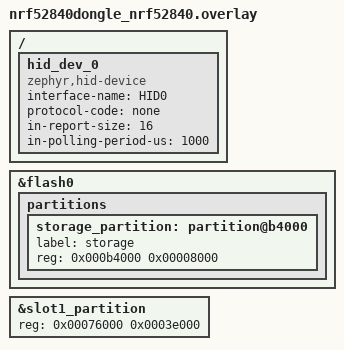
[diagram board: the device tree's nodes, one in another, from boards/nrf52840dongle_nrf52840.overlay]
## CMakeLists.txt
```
# SPDX-License-Identifier: Apache-2.0
cmake_minimum_required(VERSION 3.20.0)

find_package(Zephyr REQUIRED HINTS $ENV{ZEPHYR_BASE})
project(voice_keyboard)

target_include_directories(app PRIVATE src)
target_sources(app PRIVATE
  src/main.c
  src/usb_kbd.c
  src/ble.c
  src/inputstick.c
  # v6.0: src/typing.c (v2..v5 legacy raw ASCII/escape stream) superseded by
  # the InputStick packet protocol — removed from the build; the file stays
  # in the tree as a reference (see DEBUG_NOTES.md v6.0).
  # v5.14: src/macro.c (dongle-stored macro store) excluded — the macro
  # GATT surface hung every v5.x/v5.12/v5.13 build on hardware and is
  # removed for good; the file stays in the tree as a reference
  # (see DEBUG_NOTES.md v5.14).
)
```

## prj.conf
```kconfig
# Voice Keyboard — nRF52840 dongle (PCA10059), Adafruit UF2 bootloader

# --- UF2 drag-and-drop output; Adafruit bootloader layout (app @ 0x26000) ---
# App must stay below the storage partition (0xB4000, see boards overlay).
CONFIG_BUILD_OUTPUT_UF2=y
CONFIG_FLASH_LOAD_OFFSET=0x26000
CONFIG_FLASH_LOAD_SIZE=0x8E000

# --- USB HID keyboard (next USB device stack) ---
# The board defconfig force-enables the legacy stack + CDC ACM console;
# turn it off so only the next stack owns the USBD peripheral.
CONFIG_USB_DEVICE_STACK=n
CONFIG_USB_CDC_ACM=n
CONFIG_USB_DEVICE_STACK_NEXT=y
CONFIG_USBD_HID_SUPPORT=y

# --- BLE peripheral: NUS (defined in-app) + DIS ---
# v6.0: no pairing/bonding/encryption — SMP is removed, RX is plain write,
# and the device advertises as "InputStick" (see INPUTSTICK_EMULATION_SPEC.md).
CONFIG_BT=y
CONFIG_BT_PERIPHERAL=y
CONFIG_BT_DEVICE_NAME="InputStick"
CONFIG_BT_DIS=y
CONFIG_BT_DIS_FW_REV=y
CONFIG_BT_DIS_FW_REV_STR="vk-6.7-fix"

# --- ATT MTU headroom (added in v5 for 180-byte macro chunks; kept since
# v5.6/v5.14 after the macro store was stripped so the on-air link stays
# unchanged) ---
# Negotiated ATT MTU = min(L2CAP RX/TX MTU); defaults (65) are too small.
CONFIG_BT_BUF_ACL_RX_SIZE=200
CONFIG_BT_L2CAP_TX_MTU=200
# Keep the controller PDU length at the v4 default: BT_CTLR_DATA_LENGTH_MAX
# would otherwise follow BT_BUF_ACL_RX_SIZE to 200. The host-side MTU only
# needs L2CAP (re)assembly, so pinning this keeps the on-air link layer
# byte-identical to the hardware-verified v4 build.
CONFIG_BT_CTLR_DATA_LENGTH_MAX=27

# --- Settings/NVS (storage partition) ---
# v6.0: no bonds to persist, but the settings subsystem + storage partition
# stay so the v5.2 NVS mount/repair path in ble_init() keeps guarding
# bt_enable() against garbage flash at 0xB4000.
CONFIG_BT_SETTINGS=y
CONFIG_FLASH=y
CONFIG_FLASH_MAP=y
CONFIG_NVS=y
CONFIG_SETTINGS=y
CONFIG_SETTINGS_NVS=y

# --- Button + LED ---
CONFIG_GPIO=y

# --- Headless build: no UART console, log to SEGGER RTT ---
CONFIG_CONSOLE=n
CONFIG_SERIAL=n
CONFIG_UART_CONSOLE=n
CONFIG_LOG=y
CONFIG_LOG_DEFAULT_LEVEL=3
CONFIG_USE_SEGGER_RTT=y
CONFIG_LOG_BACKEND_RTT=y

CONFIG_MAIN_STACK_SIZE=2048
CONFIG_SYSTEM_WORKQUEUE_STACK_SIZE=2048
```

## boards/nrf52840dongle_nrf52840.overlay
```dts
/*
 * Voice Keyboard — nRF52840 dongle additions.
 * The board DTS already enables zephyr_udc0; we only need the HID device node.
 */

/ {
	hid_dev_0: hid_dev_0 {
		compatible = "zephyr,hid-device";
		interface-name = "HID0";
		/* Composite keyboard (report ID 1) + mouse (report ID 2): the
		 * report descriptor uses report IDs, which is incompatible
		 * with the HID boot protocol, so no boot protocol is claimed.
		 */
		protocol-code = "none";
		/* Longest input report: keyboard = 1 ID byte + 8 report bytes.
		 * MPS must be a power of two (16) — 9-byte keyboard reports ride
		 * as short packets on the 16-byte endpoint, normal for
		 * interrupt IN. A non-power-of-2 MPS (9) is a suspected
		 * host-side drop trigger.
		 */
		in-report-size = <16>;
		in-polling-period-us = <1000>;
	};
};

/* v5: the stock 16 KB storage partition (4 NVS sectors) cannot hold the
 * 16 KB macro store alongside the bonds (NVS needs a free
 * sector for GC). Move storage into the tail of the unused slot1 (image-1)
 * partition and enlarge it to 32 KB (8 sectors). The app is capped below
 * 0xB4000 via CONFIG_FLASH_LOAD_SIZE. Side effect: bonds stored by
 * firmware <= v4 live in the old partition and are not migrated — re-pair
 * once after flashing v5.
 */
&flash0 {
	partitions {
		/delete-node/ partition@dc000;
		storage_partition: partition@b4000 {
			label = "storage";
			reg = <0x000b4000 0x00008000>;
		};
	};
};

&slot1_partition {
	reg = <0x00076000 0x0003e000>;
};
```

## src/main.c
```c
/* Voice Keyboard — application glue: LED feedback, button, init. */

#include <zephyr/kernel.h>
#include <zephyr/drivers/gpio.h>
#include <zephyr/fatal.h>

#include <zephyr/logging/log.h>
LOG_MODULE_REGISTER(main, LOG_LEVEL_INF);

#include "vkb.h"

/* Green LED (led0): slow blink = advertising, solid = connected. */
static const struct gpio_dt_spec led = GPIO_DT_SPEC_GET(DT_ALIAS(led0), gpios);

/* Red debug LED (led1): temporary bring-up aid, see DEBUG_NOTES.md. */
static const struct gpio_dt_spec dbg_led =
	GPIO_DT_SPEC_GET_OR(DT_ALIAS(led1), gpios, {0});

/* v6.6-diagnostic: latched drain indicator (0 = never nonzero, 1 = nonzero
 * seen at least once). Set by app_drain_latch_set() from inputstick.c's
 * send_hid_status(); see DEBUG_NOTES.md v6.6-diagnostic.
 */
static atomic_t drain_latch;

static uint8_t dbg_pulses;
static uint16_t dbg_on_ms;
static uint16_t dbg_off_ms;
static bool dbg_led_on;

static void dbg_led_work_handler(struct k_work *work);

static K_WORK_DELAYABLE_DEFINE(dbg_led_work, dbg_led_work_handler);

static void dbg_led_work_handler(struct k_work *work)
{
	ARG_UNUSED(work);

	if (dbg_led_on) {
		gpio_pin_set_dt(&dbg_led, 0);
		dbg_led_on = false;
		if (dbg_pulses > 0) {
			k_work_reschedule(&dbg_led_work, K_MSEC(dbg_off_ms));
		}
		return;
	}

	if (dbg_pulses > 0) {
		dbg_pulses--;
		gpio_pin_set_dt(&dbg_led, 1);
		dbg_led_on = true;
		k_work_reschedule(&dbg_led_work, K_MSEC(dbg_on_ms));
	}
}

/* Boot-stage trace (v5.1): N slow red blinks = stage N completed, so a
 * boot hang on the headless dongle is pinpointed by the last code seen.
 * Codes (execution order, documented in DEBUG_NOTES.md):
 *   1 = main() entered, 2 = USB HID up, 3 = BLE stack up (bt_enable),
 *   4 = settings loaded, 5 = advertising up.
 * No blinks at all = death before main() (kernel/driver init).
 */
void app_boot_stage(uint8_t stage)
{
	if (dbg_led.port == NULL) {
		return;
	}

	for (uint8_t i = 0; i < stage; i++) {
		gpio_pin_set_dt(&dbg_led, 1);
		k_msleep(80);
		gpio_pin_set_dt(&dbg_led, 0);
		k_msleep(80);
	}
	k_msleep(300); /* gap between stage codes */
}

/* Boot sub-stage markers (v5.2): long (400 ms) red blinks, used for the
 * sub-steps inside ble_init()'s bt_enable() path that the short stage
 * codes can't distinguish. See DEBUG_NOTES.md.
 */
void app_boot_mark(uint8_t count)
{
	if (dbg_led.port == NULL) {
		return;
	}

	for (uint8_t i = 0; i < count; i++) {
		gpio_pin_set_dt(&dbg_led, 1);
		k_msleep(400);
		gpio_pin_set_dt(&dbg_led, 0);
		k_msleep(400);
	}
	k_msleep(300);
}

/* Repeating fast blink: bt_enable() returned an error. Never returns. */
void app_boot_error_bt(void)
{
	for (;;) {
		if (dbg_led.port != NULL) {
			gpio_pin_set_dt(&dbg_led, 1);
			k_msleep(100);
			gpio_pin_set_dt(&dbg_led, 0);
		}
		k_msleep(100);
	}
}

/* Repeating 3-long-blink group: settings storage unrecoverable even
 * after erasing the partition. Never returns.
 */
void app_boot_error_settings(void)
{
	for (;;) {
		if (dbg_led.port != NULL) {
			for (uint8_t i = 0; i < 3; i++) {
				gpio_pin_set_dt(&dbg_led, 1);
				k_msleep(400);
				gpio_pin_set_dt(&dbg_led, 0);
				k_msleep(400);
			}
		}
		k_msleep(1200);
	}
}

/* Fatal-error handler (v5.2): a fault anywhere — including inside
 * bt_enable(), where the boot-stage trace can't see it — used to die
 * silently with the red LED frozen at the last stage code (no reset:
 * CONFIG_RESET_ON_FAULT=n). Signal it with a continuous slow (1 s) red
 * blink instead. Interrupts may be disabled here, so busy-wait, never
 * k_msleep().
 */
void k_sys_fatal_error_handler(unsigned int reason, const struct arch_esf *esf)
{
	ARG_UNUSED(esf);

	LOG_ERR("Fatal error %u", reason);

	if (dbg_led.port != NULL) {
		gpio_pin_configure_dt(&dbg_led, GPIO_OUTPUT_INACTIVE);
		for (;;) {
			gpio_pin_set_dt(&dbg_led, 1);
			k_busy_wait(1000000);
			gpio_pin_set_dt(&dbg_led, 0);
			k_busy_wait(1000000);
		}
	}

	for (;;) {
		/* halt */
	}
}

void app_led_debug(enum app_led_code code)
{
	/* v6.6-diagnostic: DISABLED (no-op). The single red LED carried too
	 * many overlapping pulse codes to read on hardware (RX-write 1-blink,
	 * callback heartbeat, handshake/connect codes 9/12/13, HID fail,
	 * mouse/abs RX, and the v6.5 drain pulses). This early return silences
	 * them all; app_drain_latch_set() now drives the LED directly. The
	 * switch below is retained (not deleted) so re-enabling is a one-line
	 * revert.
	 */
	ARG_UNUSED(code);
	return;

	if (dbg_led.port == NULL) {
		return;
	}

	switch (code) {
	case APP_LED_RX_WRITE:
		dbg_on_ms = 80; dbg_off_ms = 80; dbg_pulses = 1;
		break;
	case APP_LED_HID_SENT:
		dbg_on_ms = 80; dbg_off_ms = 80; dbg_pulses = 2;
		break;
	case APP_LED_HID_FAIL:
		dbg_on_ms = 120; dbg_off_ms = 120; dbg_pulses = 3;
		break;
	case APP_LED_HID_READY:
		dbg_on_ms = 1000; dbg_off_ms = 0; dbg_pulses = 1;
		break;
	case APP_LED_MOUSE_RX:
		dbg_on_ms = 60; dbg_off_ms = 60; dbg_pulses = 4;
		break;
	case APP_LED_ABS_RX:
		dbg_on_ms = 60; dbg_off_ms = 60; dbg_pulses = 5;
		break;
	case APP_LED_MACRO_PLAY:
		dbg_on_ms = 60; dbg_off_ms = 60; dbg_pulses = 6;
		break;
	/* Connect-stage trace (v5.3): longer pulses so the counts stay
	 * distinguishable from the RX/HID codes above.
	 */
	case APP_LED_CONN_REJECT:
		dbg_on_ms = 200; dbg_off_ms = 200; dbg_pulses = 7;
		break;
	case APP_LED_SEC_FAIL:
		dbg_on_ms = 200; dbg_off_ms = 200; dbg_pulses = 8;
		break;
	case APP_LED_TX_SUB:
		dbg_on_ms = 200; dbg_off_ms = 200; dbg_pulses = 9;
		break;
	case APP_LED_NAME_READ:
		dbg_on_ms = 200; dbg_off_ms = 200; dbg_pulses = 10;
		break;
	case APP_LED_IS_CRC_FAIL:
		dbg_on_ms = 200; dbg_off_ms = 200; dbg_pulses = 2;
		break;
	case APP_LED_IS_PKT:
		dbg_on_ms = 200; dbg_off_ms = 200; dbg_pulses = 3;
		break;
	case APP_LED_IS_READY:
		dbg_on_ms = 200; dbg_off_ms = 200; dbg_pulses = 4;
		break;
	/* v6.5-diagnostic: drain-count ground truth (see DEBUG_NOTES.md
	 * v6.5-diagnostic). 3 fast blinks = a nonzero drain was computed this
	 * status interval; 1 long blink = all three drains are 0.
	 */
	case APP_LED_DRAIN_NONZERO:
		dbg_on_ms = 50; dbg_off_ms = 50; dbg_pulses = 3;
		break;
	case APP_LED_DRAIN_ZERO:
		dbg_on_ms = 200; dbg_off_ms = 0; dbg_pulses = 1;
		break;
	default:
		return;
	}

	if (!dbg_led_on) {
		k_work_reschedule(&dbg_led_work, K_NO_WAIT);
	}
}

/* v6.6-diagnostic: one-way drain latch. inputstick.c send_hid_status() calls
 * this the first time it sees any nonzero drain count; it sets the flag and
 * turns the red LED SOLID directly (no pulse work item), guarded on the LED
 * existing. Solid red = "drain went nonzero at least once"; dark red =
 * "drain always zero". The latch never clears, so solid stays solid.
 */
void app_drain_latch_set(void)
{
	atomic_set(&drain_latch, 1);
	if (dbg_led.port != NULL) {
		gpio_pin_set_dt(&dbg_led, 1);
	}
}

/* Onboard button (sw0). v5.3-v5.8: a short press opened the 60 s pairing
 * window; v5-v5.13: a long press (>1.5 s) played macro slot 0. Both are
 * gone in v6.0 (pairing removed; macro store removed in v5.14) — the button
 * is kept wired (debounced) but does nothing.
 */
static const struct gpio_dt_spec button = GPIO_DT_SPEC_GET(DT_ALIAS(sw0), gpios);

#define LONG_PRESS_MS	1500

static int64_t press_start;
static bool press_valid;

enum led_state {
	LED_OFF,
	LED_BLINK,
	LED_ON,
};

static volatile enum led_state led_state = LED_OFF;
static bool led_level;

void app_led_advertising(void)
{
	led_state = LED_BLINK;
}

void app_led_connected(void)
{
	led_state = LED_ON;
	gpio_pin_set_dt(&led, 1);
	led_level = true;
}

void app_led_off(void)
{
	led_state = LED_OFF;
	gpio_pin_set_dt(&led, 0);
	led_level = false;
}

static void led_timer_handler(struct k_timer *timer)
{
	ARG_UNUSED(timer);

	if (led_state == LED_BLINK) {
		led_level = !led_level;
		gpio_pin_set_dt(&led, led_level);
	}
}

/* 500 ms toggle -> 1 Hz blink. */
static K_TIMER_DEFINE(led_timer, led_timer_handler, NULL);

static void button_work_handler(struct k_work *work)
{
	ARG_UNUSED(work);

	/* Debounced: sample the pin after the delay. Interrupts fire on both
	 * edges, so this runs once per settled press and once per release.
	 */
	if (gpio_pin_get_dt(&button) == 1) {
		press_start = k_uptime_get();
		press_valid = true;
		return;
	}

	if (!press_valid) {
		return;
	}
	press_valid = false;

	if (k_uptime_get() - press_start >= LONG_PRESS_MS) {
		LOG_INF("Long press ignored (no macro store, no pairing)");
		return;
	}

	LOG_INF("Button pressed (no action in v6.0)");
}

static K_WORK_DELAYABLE_DEFINE(button_work, button_work_handler);

static void button_isr(const struct device *dev,
		       struct gpio_callback *cb, uint32_t pins)
{
	ARG_UNUSED(dev); ARG_UNUSED(cb); ARG_UNUSED(pins);

	k_work_reschedule(&button_work, K_MSEC(30));
}

static struct gpio_callback button_cb_data;

static int button_init(void)
{
	int ret;

	if (!gpio_is_ready_dt(&button)) {
		LOG_ERR("Button device not ready");
		return -ENODEV;
	}

	ret = gpio_pin_configure_dt(&button, GPIO_INPUT);
	if (ret) {
		return ret;
	}

	ret = gpio_pin_interrupt_configure_dt(&button, GPIO_INT_EDGE_BOTH);
	if (ret) {
		return ret;
	}

	gpio_init_callback(&button_cb_data, button_isr, BIT(button.pin));
	gpio_add_callback(button.port, &button_cb_data);

	return 0;
}

int main(void)
{
	int ret;

	if (gpio_is_ready_dt(&led)) {
		gpio_pin_configure_dt(&led, GPIO_OUTPUT_INACTIVE);
	} else {
		LOG_WRN("LED not available, continuing without it");
	}

	if (dbg_led.port != NULL && gpio_is_ready_dt(&dbg_led)) {
		gpio_pin_configure_dt(&dbg_led, GPIO_OUTPUT_INACTIVE);
	}

	k_timer_start(&led_timer, K_MSEC(500), K_MSEC(500));

	app_boot_stage(1);

	ret = button_init();
	if (ret) {
		LOG_ERR("Button init failed (%d), continuing without it", ret);
	}

	ret = usb_kbd_init();
	if (ret) {
		LOG_ERR("USB init failed (%d)", ret);
		return ret;
	}

	app_boot_stage(2);

	ret = ble_init();
	if (ret) {
		LOG_ERR("BLE init failed (%d)", ret);
		return ret;
	}

	LOG_INF("Voice Keyboard ready");
	return 0;
}
```

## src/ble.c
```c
/* Voice Keyboard — BLE peripheral (v6.0).
 *
 * Plain NUS peripheral: the standard Nordic UART service UUIDs with
 * unencrypted RX writes and no pairing/bonding — the InputStick iOS/Android
 * apps connect and write plaintext (see INPUTSTICK_EMULATION_SPEC.md §2).
 * The v5.3–v5.8 encryption/bonding machinery (bonded-peer gate, 60 s pairing
 * window, forced bt_conn_set_security, DisplayYesNo numeric-comparison
 * pairing, BT_GATT_PERM_WRITE_ENCRYPT) is stripped. The device advertises as
 * "InputStick".
 *
 * v5.14 removed the v5 MACRO_LIST/MACRO_RW macro-store characteristics for
 * good; macro.c stays in the tree as a reference but is excluded from the
 * build (see DEBUG_NOTES.md v5.14).
 */

#include <zephyr/kernel.h>
#include <zephyr/bluetooth/bluetooth.h>
#include <zephyr/bluetooth/conn.h>
#include <zephyr/bluetooth/gatt.h>
#include <zephyr/bluetooth/uuid.h>
#include <zephyr/settings/settings.h>
#include <zephyr/storage/flash_map.h>
#include <zephyr/sys/util.h>

#include <string.h>

#include <zephyr/logging/log.h>
LOG_MODULE_REGISTER(ble, LOG_LEVEL_INF);

#include "vkb.h"

/* Zephyr keeps settings_subsys_init() out of the public headers
 * (subsys/settings/src/settings_init.c). bt_enable() calls it internally
 * via bt_settings_init(); declared here so ble_init() can mount the
 * settings backend first — see ble_init().
 */
extern int settings_subsys_init(void);

/* Standard NUS UUIDs (we define the service in-app so the RX
 * characteristic uses plain BT_GATT_PERM_WRITE — Zephyr's built-in NUS
 * is equivalent, but defining it keeps the attribute layout explicit).
 */
#define VKB_UUID_NUS_SERVICE \
	BT_UUID_DECLARE_128(BT_UUID_128_ENCODE(0x6e400001, 0xb5a3, 0xf393, 0xe0a9, 0xe50e24dcca9e))
#define VKB_UUID_NUS_RX \
	BT_UUID_DECLARE_128(BT_UUID_128_ENCODE(0x6e400002, 0xb5a3, 0xf393, 0xe0a9, 0xe50e24dcca9e))
#define VKB_UUID_NUS_TX \
	BT_UUID_DECLARE_128(BT_UUID_128_ENCODE(0x6e400003, 0xb5a3, 0xf393, 0xe0a9, 0xe50e24dcca9e))

/* Fixed advertising/GAP name. */
#define DEVICE_NAME_DEFAULT	"InputStick"

static struct bt_conn *current_conn;
static bool tx_notif_enabled;

static ssize_t nus_rx_write(struct bt_conn *conn,
			    const struct bt_gatt_attr *attr,
			    const void *buf, uint16_t len,
			    uint16_t offset, uint8_t flags)
{
	ARG_UNUSED(conn); ARG_UNUSED(attr); ARG_UNUSED(offset); ARG_UNUSED(flags);

	app_led_debug(APP_LED_RX_WRITE);
	inputstick_feed(buf, len);
	return len;
}

static void nus_tx_ccc_changed(const struct bt_gatt_attr *attr, uint16_t value)
{
	ARG_UNUSED(attr);

	tx_notif_enabled = (value == BT_GATT_CCC_NOTIFY);
	if (tx_notif_enabled) {
		app_led_debug(APP_LED_TX_SUB);
	}
}

BT_GATT_SERVICE_DEFINE(nus_svc,
	BT_GATT_PRIMARY_SERVICE(VKB_UUID_NUS_SERVICE),
	BT_GATT_CHARACTERISTIC(VKB_UUID_NUS_TX,
		BT_GATT_CHRC_NOTIFY,
		BT_GATT_PERM_NONE,
		NULL, NULL, NULL),
	BT_GATT_CCC(nus_tx_ccc_changed,
		BT_GATT_PERM_READ | BT_GATT_PERM_WRITE),
	BT_GATT_CHARACTERISTIC(VKB_UUID_NUS_RX,
		BT_GATT_CHRC_WRITE | BT_GATT_CHRC_WRITE_WITHOUT_RESP,
		BT_GATT_PERM_WRITE,
		NULL, nus_rx_write, NULL),
);

/* Advertising data carries the fixed compiled-in name. */
static struct bt_data ad[] = {
	BT_DATA_BYTES(BT_DATA_FLAGS, BT_LE_AD_GENERAL | BT_LE_AD_NO_BREDR),
	{
		.type = BT_DATA_NAME_COMPLETE,
		.data_len = sizeof(DEVICE_NAME_DEFAULT) - 1,
		.data = (const uint8_t *)DEVICE_NAME_DEFAULT,
	},
};

static const struct bt_data sd[] = {
	BT_DATA_BYTES(BT_DATA_UUID128_ALL,
		      BT_UUID_128_ENCODE(0x6e400001, 0xb5a3, 0xf393,
					 0xe0a9, 0xe50e24dcca9e)),
};

static void start_advertising(void)
{
	int err = bt_le_adv_start(BT_LE_ADV_CONN_FAST_2, ad, ARRAY_SIZE(ad),
				  sd, ARRAY_SIZE(sd));
	if (err) {
		LOG_ERR("Advertising failed to start (%d)", err);
		return;
	}

	app_led_advertising();
	LOG_INF("Advertising started");
}

/* --- Connection management --- */

static void connected(struct bt_conn *conn, uint8_t err)
{
	if (err) {
		LOG_ERR("Connection failed (err 0x%02x)", err);
		return;
	}

	current_conn = bt_conn_ref(conn);
	app_led_connected();
	LOG_INF("Connected");
}

static void disconnected(struct bt_conn *conn, uint8_t reason)
{
	ARG_UNUSED(conn);

	LOG_INF("Disconnected (reason 0x%02x)", reason);

	if (current_conn) {
		bt_conn_unref(current_conn);
		current_conn = NULL;
	}

	tx_notif_enabled = false;
	inputstick_reset();
	start_advertising();
}

BT_CONN_CB_DEFINE(conn_cbs) = {
	.connected = connected,
	.disconnected = disconnected,
};

/* --- Notifications ---------------------------------------------------------
 *
 * bt_gatt_notify() must never run on the BT RX thread (GATT write/CCC
 * callbacks included): for a notification it allocates a PDU from att_pool
 * (CONFIG_BT_ATT_TX_COUNT=3 here) with K_FOREVER unless the caller is the
 * system workqueue (Zephyr 4.1 att.c bt_att_chan_create_pdu()), and those
 * buffers are freed by ATT TX completion processing on that same RX thread.
 * A notify from inside a callback can therefore block the RX thread forever
 * and kill the whole ATT server — the v5.3/v5.4 hang. All notifications are
 * queued (K_MSGQ) and sent from the system workqueue, where the allocation
 * is K_NO_WAIT and the worst case is a dropped (best-effort) packet.
 *
 * nus_svc attribute layout:
 *   attrs[0] primary service, attrs[1] TX declaration,
 *   attrs[2] TX value, attrs[3] TX CCC,
 *   attrs[4] RX declaration, attrs[5] RX value.
 * Notifications must be sent on the VALUE attribute (attrs[2]); using
 * attrs[1] notifies the declaration handle, which no central subscribes to,
 * so every packet is silently dropped.
 */

#define BLE_NOTIFY_MAX_LEN	274 /* 2 (tag+hdr) + 272 (max payload) */
/* The peer never negotiates ATT MTU, so it stays 23 = a 20-byte notification
 * payload. Zephyr drops any ATT PDU with len + 1 > MTU, so every packet is
 * split into <=20-byte notifications (the peer's PacketReader reassembles
 * the byte stream, so chunk boundaries are arbitrary).
 */
#define BLE_NOTIFY_CHUNK	20

struct ble_notify_msg {
	uint16_t len;
	uint8_t data[BLE_NOTIFY_MAX_LEN];
};

K_MSGQ_DEFINE(ble_notify_msgq, sizeof(struct ble_notify_msg), 4, 4);

static void notify_work_fn(struct k_work *work)
{
	ARG_UNUSED(work);

	struct ble_notify_msg msg;

	while (k_msgq_get(&ble_notify_msgq, &msg, K_NO_WAIT) == 0) {
		if (!current_conn || !tx_notif_enabled) {
			continue;
		}

		/* Chunk the packet into <=20-byte notifies (see
		 * BLE_NOTIFY_CHUNK): the whole InputStick packet must be
		 * emitted in order, but the chunk boundaries are arbitrary.
		 */
		for (uint16_t off = 0; off < msg.len; off += BLE_NOTIFY_CHUNK) {
			uint16_t chunk = MIN(msg.len - off, BLE_NOTIFY_CHUNK);
			int err = bt_gatt_notify(current_conn,
						 &nus_svc.attrs[2],
						 msg.data + off, chunk);

			if (err) {
				LOG_WRN("Notify failed (%d)", err);
			}
		}
	}
}

static K_WORK_DEFINE(notify_work, notify_work_fn);

/* Queue a packet for TX notify; the actual notify runs on the system
 * workqueue. Safe to call from any non-BT-RX thread (best effort).
 */
int ble_notify(const void *data, uint16_t len)
{
	if (len > BLE_NOTIFY_MAX_LEN) {
		return -EINVAL;
	}

	struct ble_notify_msg msg;

	msg.len = len;
	memcpy(msg.data, data, len);

	if (k_msgq_put(&ble_notify_msgq, &msg, K_NO_WAIT) != 0) {
		LOG_WRN("Notify queue full, dropped");
		return -EAGAIN;
	}

	k_work_submit(&notify_work);
	return 0;
}

bool ble_is_connected(void)
{
	return current_conn != NULL;
}

/* Erase the whole settings storage partition. Used to recover from a
 * failed NVS mount on flash that previously held something else.
 */
static int storage_partition_erase(void)
{
	const struct flash_area *fa;
	int err = flash_area_open(FIXED_PARTITION_ID(storage_partition), &fa);

	if (err) {
		return err;
	}
	err = flash_area_flatten(fa, 0, fa->fa_size);
	flash_area_close(fa);
	return err;
}

int ble_init(void)
{
	int err;

	/* v5 moved the settings partition to 0xB4000, a flash region that
	 * older firmware could legally occupy or that may carry DFU residue.
	 * bt_enable() -> bt_init() -> bt_settings_init() mounts NVS on it and
	 * ABORTS bt_enable() on any mount error. Mount it ourselves first; on
	 * failure erase the partition and retry, so the mount always sees a
	 * valid (empty) NVS. A repair erase loses any stored settings.
	 */
	app_boot_mark(1);
	err = settings_subsys_init();
	if (err) {
		LOG_WRN("Settings mount failed (%d), erasing storage partition",
			err);
		app_boot_mark(2);
		err = storage_partition_erase();
		if (!err) {
			err = settings_subsys_init();
		}
		if (err) {
			LOG_ERR("Settings storage unrecoverable (%d)", err);
			app_boot_error_settings();
		}
		LOG_INF("Settings storage repaired");
	}

	err = bt_enable(NULL);
	if (err) {
		LOG_ERR("Bluetooth init failed (%d)", err);
		app_boot_error_bt();
	}
	app_boot_stage(3);

	if (IS_ENABLED(CONFIG_BT_SETTINGS)) {
		settings_load();
	}
	app_boot_stage(4);

	start_advertising();
	app_boot_stage(5);
	return 0;
}
```

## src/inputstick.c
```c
/* Voice Keyboard — InputStick protocol layer (v6.0).
 *
 * Speaks the InputStick packet protocol (see INPUTSTICK_EMULATION_SPEC.md)
 * on top of the NUS RX/TX characteristics so the free InputStick iOS/Android
 * apps connect, reach "Ready", and type. This replaces the v2..v5 legacy raw
 * ASCII/escape byte stream (typing.c) — v6 speaks InputStick only.
 *
 * Framing (spec §3):
 *   byte 0       : 0x55 start tag
 *   byte 1       : header = (length in 16-byte blocks, bits 0..5)
 *                          | flags (0x80 response, 0x40 encrypted, 0x20 HMAC)
 *   bytes 2..N-1 : payload, 16*blocks bytes, zero-padded:
 *                     payload[0..3]  CRC32 (IEEE 802.3 / zlib) big-endian,
 *                                    over payload[4..end]
 *                     payload[4]     command
 *                     payload[5]     param / response-code
 *                     payload[6..]   data
 *                  Notifications (dongle->app) omit the param byte:
 *                     data starts at payload[5].
 *
 * Threading (the v5.4 lesson): the byte-wise parser runs on the BT RX thread
 * (cheap: scan + CRC). Each complete, CRC-valid packet is queued to a
 * dedicated dispatch thread, which performs the blocking USB HID submits and
 * builds responses; bt_gatt_notify() is never called from the BT RX thread.
 */

#include <zephyr/kernel.h>
#include <zephyr/sys/crc.h>
#include <zephyr/sys/ring_buffer.h>
#include <zephyr/sys/util.h>
#include <string.h>

#include <zephyr/logging/log.h>
LOG_MODULE_REGISTER(inputstick, LOG_LEVEL_INF);

#include "vkb.h"

/* --- framing constants (spec §3) --- */
#define IS_TAG			0x55
#define IS_FLAG_HMAC		0x20
#define IS_FLAG_ENCRYPTED	0x40
#define IS_FLAG_RESPONSE	0x80
#define IS_MAX_BLOCKS		17
#define IS_BLOCK_SIZE		16
#define IS_MAX_PAYLOAD		(IS_MAX_BLOCKS * IS_BLOCK_SIZE) /* 272 */
#define IS_MAX_PACKET		(2 + IS_MAX_PAYLOAD)            /* 274 */

/* --- commands (spec §4) --- */
#define IS_CMD_IDENTIFY		0x01
#define IS_CMD_RUN_FIRMWARE	0x04
#define IS_CMD_GET_FW_INFO	0x10
#define IS_CMD_INIT		0x11	/* Android CMD_INIT = iOS WdgReset */
#define IS_CMD_HID_REQ_STATUS	0x20
#define IS_CMD_HID_KBD		0x21
#define IS_CMD_HID_CONSUMER	0x22
#define IS_CMD_HID_MOUSE	0x23
#define IS_CMD_HID_TOUCH	0x26
#define IS_CMD_HID_CLEAR	0x2A
#define IS_CMD_HID_KBD_SHORT	0x2C
#define IS_CMD_HID_STATUS_NOTIF	0x2F
#define IS_CMD_SET_UPDATE_INTERVAL 0x31

#define IS_RESP_OK		0x01

/* Keystroke pacing for the dictation path. v6.4: no per-keystroke sleep is
 * needed on the dispatch thread — KeyboardShort (0x2C) is forwarded 1:1 as
 * a USB keyboard-state report, and the non-blocking HID FIFO (usb_kbd.c)
 * paces the USB output natively (single in-flight report + 1 ms
 * interrupt-IN polling preserves report order). KEY_GAP_MS was removed in
 * v6.3; KEY_PRESS_MS had no remaining callers after tap() became a pure
 * state-report forward, so it is removed too.
 */

/* RX queue: complete packets handed from the BT RX thread to the dispatch
 * thread. 8 KB holds ~430 keyboard-short packets or ~29 max-size packets;
 * flow control (M3) will revisit this sizing.
 */
#define IS_RX_RING_SIZE	8192

RING_BUF_DECLARE(is_ring, IS_RX_RING_SIZE);
K_SEM_DEFINE(is_sem, 0, 64);

/* --- parser state (BT RX thread only) --- */
enum is_parse_state {
	IS_STATE_TAG,     /* scanning for 0x55 */
	IS_STATE_HEADER,  /* got 0x55, reading the header byte */
	IS_STATE_PAYLOAD, /* accumulating payload bytes */
};

static enum is_parse_state parse_state = IS_STATE_TAG;
static uint8_t pkt_payload[IS_MAX_PAYLOAD];
static uint16_t pkt_total; /* payload bytes to read = blocks * 16 */
static uint16_t pkt_len;   /* bytes accumulated so far */
static uint8_t pkt_flags;

/* Handshake / ready state (dispatch thread + USBD thread). */
static atomic_t handshake_done; /* SetUpdateInterval received */
static atomic_t ready_sent;     /* Ready HIDStatusNotification emitted */

/* Periodic HIDStatusNotification: interval from SetUpdateInterval (0x31),
 * in units of 100 ms (param 4 = 400 ms); default 400 ms. The k_timer fires
 * at that rate and defers the actual notify to the system workqueue.
 */
static atomic_t status_interval_ms = 400;

static void status_timer_expired(struct k_timer *timer);
static void status_work_fn(struct k_work *work);
static K_TIMER_DEFINE(status_timer, status_timer_expired, NULL);
static K_WORK_DEFINE(status_work, status_work_fn);

static void start_status_timer(void)
{
	uint32_t iv = atomic_get(&status_interval_ms);

	if (iv == 0) {
		iv = 400;
	}
	k_timer_start(&status_timer, K_MSEC(iv), K_MSEC(iv));
}

/* Set by inputstick_reset() on the BT RX thread, honoured by the dispatch
 * thread (mirrors the typing.c reset_pending pattern).
 */
static atomic_t reset_pending;

/* --- packet building (dispatch thread) -------------------------------- */

static void build_payload(uint8_t *pl, uint16_t total, uint8_t cmd,
			  uint8_t param, const uint8_t *data, uint16_t data_len,
			  bool has_param)
{
	memset(pl, 0, total);
	pl[4] = cmd;
	if (has_param) {
		pl[5] = param;
		if (data && data_len) {
			memcpy(pl + 6, data, data_len);
		}
	} else if (data && data_len) {
		memcpy(pl + 5, data, data_len);
	}

	/* CRC over command(+param)+data+zero padding = pl[4..total-1]. */
	uint32_t crc = crc32_ieee(&pl[4], total - 4);

	pl[0] = (uint8_t)(crc >> 24);
	pl[1] = (uint8_t)(crc >> 16);
	pl[2] = (uint8_t)(crc >> 8);
	pl[3] = (uint8_t)crc;
}

/* Build a normal packet (command + param + data) into out; sets *out_len. */
static void build_packet(uint8_t cmd, uint8_t param, const uint8_t *data,
			 uint16_t data_len, uint8_t *out, uint16_t *out_len)
{
	uint16_t payload = 6 + data_len; /* CRC + cmd + param + data */
	uint16_t blocks = (uint16_t)(((payload - 1) >> 4) + 1);
	uint16_t total = blocks * IS_BLOCK_SIZE;

	out[0] = IS_TAG;
	out[1] = (uint8_t)blocks; /* flags = 0: no response/encrypt/HMAC */
	build_payload(out + 2, total, cmd, param, data, data_len, true);
	*out_len = 2 + total;
}

/* Build a notification packet (command + data, no param byte). */
static void build_notification(uint8_t cmd, const uint8_t *data,
			       uint16_t data_len, uint8_t *out,
			       uint16_t *out_len)
{
	uint16_t payload = 5 + data_len; /* CRC + cmd + data */
	uint16_t blocks = (uint16_t)(((payload - 1) >> 4) + 1);
	uint16_t total = blocks * IS_BLOCK_SIZE;

	out[0] = IS_TAG;
	out[1] = (uint8_t)blocks;
	build_payload(out + 2, total, cmd, 0, data, data_len, false);
	*out_len = 2 + total;
}

static void is_send(uint8_t cmd, uint8_t param, const uint8_t *data,
		    uint16_t data_len)
{
	uint8_t pkt[IS_MAX_PACKET];
	uint16_t len;

	build_packet(cmd, param, data, data_len, pkt, &len);
	ble_notify(pkt, len);
}

static int is_send_notification(uint8_t cmd, const uint8_t *data,
				uint16_t data_len)
{
	uint8_t pkt[IS_MAX_PACKET];
	uint16_t len;

	build_notification(cmd, data, data_len, pkt, &len);
	return ble_notify(pkt, len);
}

static void is_respond(uint8_t cmd, uint8_t resp_code, const uint8_t *data,
		       uint16_t data_len)
{
	is_send(cmd, resp_code, data, data_len);
}

/* --- handshake responses (spec §5, §5.1, §7, §9b) ---------------------- */

static void respond_fw_info(void)
{
	uint8_t info[19];

	memset(info, 0, sizeof(info));
	info[0] = 1;  /* firmwareType */
	info[1] = 1;  /* versionMajor */
	info[2] = 1;  /* versionMinor -> firmware version 101 */
	info[3] = 0;  /* versionHardware */
	/* info[4..16] reserved, zero */
	info[17] = 0x00; /* securityStatus */
	info[18] = 0x00; /* passwordProtection: no password -> skip auth */

	is_respond(IS_CMD_GET_FW_INFO, IS_RESP_OK, info, sizeof(info));
}

static void send_hid_status(void)
{
	uint8_t st[11];
	uint8_t kbd_drained, mouse_drained, consumer_drained;

	memset(st, 0, sizeof(st));
	st[0] = 0x05;  /* USB state = USBConfigured */
	st[1] = 0x00;  /* keyboard LEDs */
	st[2] = 0x01;  /* keyboard protocol: 1 = report protocol */
	st[3] = 0x01;  /* keyboard buffer empty */
	st[4] = 0x01;  /* mouse protocol: 1 = report protocol */
	st[5] = 0x01;  /* mouse buffer empty */
	st[6] = 0x01;  /* consumer buffer empty */
	/* st[7..9] = reports sent to host since the last notify (the drain
	 * counts the app uses to replenish its free-space counters).
	 *
	 * v6.7: PEEK (read without reset) the deltas, then only COMMIT
	 * (subtract) them once the 0x2F has been accepted into the notify
	 * queue. If the queue is full the counters are left intact so the
	 * next status reports the accumulated total (self-healing) — a
	 * dropped 0x2F can no longer permanently lose up to 255 credits.
	 */
	usb_hid_drain_counts_peek(&kbd_drained, &mouse_drained, &consumer_drained);
	st[7] = kbd_drained;
	st[8] = mouse_drained;
	st[9] = consumer_drained;
	st[10] = 0xFF; /* sent-to-host gate: USB Remote reads data[11]==0xFF
			* (= offset +10) before trusting st[7..9] */

	/* v6.6-diagnostic: log the raw drain deltas every status interval (RTT
	 * ground truth) and latch the red LED SOLID the first time any drain
	 * count is nonzero. The latch is one-way and drives the LED directly
	 * (app_led_debug is now a no-op), so a solid red LED is an unambiguous
	 * "drain went nonzero at least once" signal with all other red-LED
	 * noise removed. See DEBUG_NOTES.md v6.6-diagnostic.
	 */
	LOG_INF("HID status: drain kbd=%u mouse=%u consumer=%u",
		kbd_drained, mouse_drained, consumer_drained);
	if (kbd_drained || mouse_drained || consumer_drained) {
		app_drain_latch_set();
	}

	if (is_send_notification(IS_CMD_HID_STATUS_NOTIF, st,
				 sizeof(st)) == 0) {
		usb_hid_drain_counts_commit(kbd_drained, mouse_drained,
					    consumer_drained);
	}
}

static void try_send_ready(void)
{
	if (atomic_get(&ready_sent)) {
		return;
	}
	if (!atomic_get(&handshake_done)) {
		return;
	}
	if (!usb_kbd_ready()) {
		return;
	}

	atomic_set(&ready_sent, 1);
	send_hid_status();
	start_status_timer();
	app_led_debug(APP_LED_IS_READY);
	LOG_INF("Ready: HIDStatusNotification (USBConfigured) sent");
}

/* Timer expiry runs in ISR context; the actual notify is deferred to the
 * system workqueue (bt_gatt_notify must not run on the BT RX thread, and
 * keep the ISR path minimal).
 */
static void status_timer_expired(struct k_timer *timer)
{
	ARG_UNUSED(timer);

	k_work_submit(&status_work);
}

static void status_work_fn(struct k_work *work)
{
	ARG_UNUSED(work);

	send_hid_status();
}

/* --- HID report mapping (spec §6) -------------------------------------- */

/* KeyboardShort (0x2C): [modifiers, keycode] is the *current* keyboard
 * state (spec §2.2 / USB_REMOTE_AND_PROTOCOL_DOCS.md:187-197). Forward it
 * as exactly one USB report so the per-interface drain count stays 1:1 with
 * the app's per-report freeSpace decrement. The next report releases the
 * previous key; do NOT expand into press+release and do NOT skip key==0, or
 * kbd_sent (2/char) under-reports the app's 3/char and freeSpace leaks to 0.
 */
static void tap(uint8_t mods, uint8_t key)
{
	usb_kbd_report(mods, key);
}

static void hid_kbd_short(const uint8_t *data, uint16_t data_len, uint8_t n)
{
	uint8_t count = MIN(n, (uint8_t)(data_len / 2));

	for (uint8_t i = 0; i < count; i++) {
		tap(data[i * 2], data[i * 2 + 1]);
	}
}

/* Keyboard (0x21): [mods, 0x00, key0..key5] — a press report (the app sends
 * its own release); we forward the first key (single-key rollover).
 */
static void hid_kbd(const uint8_t *data, uint16_t data_len, uint8_t n)
{
	uint8_t count = MIN(n, (uint8_t)(data_len / 8));

	for (uint8_t i = 0; i < count; i++) {
		const uint8_t *r = &data[i * 8];

		usb_kbd_report(r[0], r[2]);
	}
}

/* Mouse (0x23): [buttons, dx, dy, scroll]. */
static void hid_mouse(const uint8_t *data, uint16_t data_len, uint8_t n)
{
	uint8_t count = MIN(n, (uint8_t)(data_len / 4));

	for (uint8_t i = 0; i < count; i++) {
		const uint8_t *r = &data[i * 4];

		app_led_debug(APP_LED_MOUSE_RX);
		usb_mouse_report(r[0], (int8_t)r[1], (int8_t)r[2],
				 (int8_t)r[3]);
	}
}

/* TouchScreen (0x26): [reportID=4, tip+in_range, x_lsb, x_msb, y_lsb, y_msb].
 * x/y are 16-bit (0..65535); ours are 15-bit (0..32767) -> scale by 1 bit.
 */
static void hid_touch(const uint8_t *data, uint16_t data_len, uint8_t n)
{
	uint8_t count = MIN(n, (uint8_t)(data_len / 6));

	for (uint8_t i = 0; i < count; i++) {
		const uint8_t *r = &data[i * 6];
		uint8_t buttons = (r[1] & 0x01) ? 0x01 : 0x00; /* tip = left */
		uint16_t x = (uint16_t)(r[2] | (r[3] << 8));
		uint16_t y = (uint16_t)(r[4] | (r[5] << 8));

		app_led_debug(APP_LED_ABS_RX);
		usb_abs_report(buttons, (uint16_t)(x >> 1),
			       (uint16_t)(y >> 1));
	}
}

/* Consumer (0x22): [reportID, usageLSB, usageMSB] per report.
 * reportID 1 = Consumer page (media keys: Play/Pause 0xCD, Vol+ 0xE9,
 * Vol- 0xEA, Mute 0xE2, next 0xB5, prev 0xB6, …) -> USB consumer report.
 * reportID 2 = System page (power/sleep/wake) -> no System Control collection
 * in this build's descriptor, so it cannot be forwarded as a real USB report;
 * instead credit consumer_sent directly (usb_hid_consumer_credit) so the
 * app's per-report consumer freeSpace stays 1:1 and never leaks. Any other
 * report ID is ignored (no credit — not produced by the app).
 */
static void hid_consumer(const uint8_t *data, uint16_t data_len, uint8_t n)
{
	uint8_t count = MIN(n, (uint8_t)(data_len / 3));

	for (uint8_t i = 0; i < count; i++) {
		const uint8_t *r = &data[i * 3];
		uint16_t usage = (uint16_t)(r[1] | (r[2] << 8));

		if (r[0] == 1) {
			usb_consumer_report(usage);
		} else if (r[0] == 2) {
			usb_hid_consumer_credit(1);
		}
	}
}

/* --- command dispatch (spec §4) ---------------------------------------- */

static void dispatch_packet(const uint8_t *payload, uint16_t total,
			    uint8_t flags)
{
	uint32_t crc_rx = ((uint32_t)payload[0] << 24) |
			  ((uint32_t)payload[1] << 16) |
			  ((uint32_t)payload[2] << 8) |
			  (uint32_t)payload[3];
	uint32_t crc_calc = crc32_ieee(&payload[4], total - 4);

	if (crc_rx != crc_calc) {
		LOG_WRN("CRC mismatch (rx 0x%08x calc 0x%08x)", crc_rx,
			crc_calc);
		app_led_debug(APP_LED_IS_CRC_FAIL);
		return;
	}

	if (flags & (IS_FLAG_ENCRYPTED | IS_FLAG_HMAC)) {
		LOG_WRN("encrypted/HMAC packet unsupported, dropped");
		return;
	}

	uint8_t cmd = payload[4];
	uint8_t param = payload[5];
	const uint8_t *data = &payload[6];
	uint16_t data_len = total - 6; /* includes zero padding */
	bool respond = (flags & IS_FLAG_RESPONSE) != 0;

	/* LED trace: blink on control/handshake packets, not HID bursts. */
	switch (cmd) {
	case IS_CMD_HID_KBD_SHORT:
	case IS_CMD_HID_KBD:
	case IS_CMD_HID_CONSUMER:
	case IS_CMD_HID_MOUSE:
	case IS_CMD_HID_TOUCH:
		break;
	default:
		app_led_debug(APP_LED_IS_PKT);
		break;
	}

	switch (cmd) {
	case IS_CMD_RUN_FIRMWARE:
		is_respond(IS_CMD_RUN_FIRMWARE, IS_RESP_OK, NULL, 0);
		break;
	case IS_CMD_GET_FW_INFO:
		respond_fw_info();
		break;
	case IS_CMD_INIT:
		is_respond(IS_CMD_INIT, IS_RESP_OK, NULL, 0);
		break;
	case IS_CMD_SET_UPDATE_INTERVAL:
		if (respond) {
			is_respond(IS_CMD_SET_UPDATE_INTERVAL, IS_RESP_OK,
				   NULL, 0);
		}
		/* param is in units of 100 ms (param 4 = 400 ms). */
		{
			uint32_t iv = (uint32_t)param * 100U;

			atomic_set(&status_interval_ms, iv ? iv : 400U);
		}
		atomic_set(&handshake_done, 1);
		if (atomic_get(&ready_sent)) {
			/* Re-issued interval after Ready: restart the timer. */
			start_status_timer();
		} else {
			try_send_ready();
		}
		break;
	case IS_CMD_HID_REQ_STATUS:
		send_hid_status();
		break;
	case IS_CMD_HID_KBD_SHORT:
		hid_kbd_short(data, data_len, param);
		break;
	case IS_CMD_HID_KBD:
		hid_kbd(data, data_len, param);
		break;
	case IS_CMD_HID_CONSUMER:
		hid_consumer(data, data_len, param);
		break;
	case IS_CMD_HID_MOUSE:
		hid_mouse(data, data_len, param);
		break;
	case IS_CMD_HID_TOUCH:
		hid_touch(data, data_len, param);
		break;
	case IS_CMD_HID_CLEAR:
		/* No report buffer in M2 -> nothing to clear. */
		if (respond) {
			is_respond(IS_CMD_HID_CLEAR, IS_RESP_OK, NULL, 0);
		}
		break;
	case IS_CMD_IDENTIFY:
		/* "Find device": the packet blink above already pulses the
		 * LED; reply defensively if a response was requested. The
		 * management screen requires data[0] == 0x42 ('B' = firmware
		 * running) to proceed.
		 */
		if (respond) {
			uint8_t mode = 0x42;

			is_respond(IS_CMD_IDENTIFY, IS_RESP_OK, &mode, 1);
		}
		break;
	default:
		if (respond) {
			is_respond(cmd, IS_RESP_OK, NULL, 0);
		}
		break;
	}
}

/* --- dispatch thread ---------------------------------------------------- */

static void queue_packet(void)
{
	uint32_t need = 3 + pkt_total; /* len(2) + flags(1) + payload */

	if (ring_buf_space_get(&is_ring) < need) {
		LOG_WRN("inputstick RX ring overflow, dropped packet");
		return;
	}

	uint8_t hdr[3] = {
		(uint8_t)(pkt_total & 0xFF),
		(uint8_t)(pkt_total >> 8),
		pkt_flags,
	};

	ring_buf_put(&is_ring, hdr, sizeof(hdr));
	ring_buf_put(&is_ring, pkt_payload, pkt_total);
	k_sem_give(&is_sem);
}

static void dispatch_thread(void *p1, void *p2, void *p3)
{
	ARG_UNUSED(p1); ARG_UNUSED(p2); ARG_UNUSED(p3);

	while (true) {
		uint8_t hdr[3];
		uint8_t payload[IS_MAX_PAYLOAD];
		uint32_t n;

		k_sem_take(&is_sem, K_FOREVER);

		if (atomic_get(&reset_pending)) {
			atomic_set(&reset_pending, 0);
			atomic_set(&handshake_done, 0);
			atomic_set(&ready_sent, 0);
			atomic_set(&status_interval_ms, 400);
			k_timer_stop(&status_timer);
			ring_buf_reset(&is_ring);
			continue;
		}

		n = ring_buf_get(&is_ring, hdr, sizeof(hdr));
		if (n < sizeof(hdr)) {
			continue;
		}

		uint16_t total = (uint16_t)(hdr[0] | (hdr[1] << 8));
		uint8_t flags = hdr[2];

		if (total < IS_BLOCK_SIZE || total > IS_MAX_PAYLOAD) {
			continue;
		}

		n = ring_buf_get(&is_ring, payload, total);
		if (n < total) {
			continue;
		}

		dispatch_packet(payload, total, flags);
	}
}

K_THREAD_DEFINE(is_tid, 3072, dispatch_thread, NULL, NULL, NULL,
		K_PRIO_PREEMPT(8), 0, 0);

/* --- public entry points ------------------------------------------------ */

/* Byte-wise parser, mirroring InputStickPacketParser.m. Runs on the BT RX
 * thread (nus_rx_write); cheap scan + CRC, no notify, no blocking HID.
 */
void inputstick_feed(const void *buf, uint16_t len)
{
	const uint8_t *p = buf;

	for (uint16_t i = 0; i < len; i++) {
		uint8_t b = p[i];

		switch (parse_state) {
		case IS_STATE_TAG:
			if (b == IS_TAG) {
				parse_state = IS_STATE_HEADER;
			}
			break;

		case IS_STATE_HEADER: {
			uint8_t blocks = b & 0x3F;

			pkt_flags = b & 0xE0;
			if (blocks < 1 || blocks > IS_MAX_BLOCKS) {
				parse_state = IS_STATE_TAG;
				break;
			}
			pkt_total = blocks * IS_BLOCK_SIZE;
			pkt_len = 0;
			parse_state = IS_STATE_PAYLOAD;
			break;
		}

		case IS_STATE_PAYLOAD:
			pkt_payload[pkt_len++] = b;
			if (pkt_len == pkt_total) {
				queue_packet();
				parse_state = IS_STATE_TAG;
			}
			break;
		}
	}
}

/* Called from ble.c's disconnected() (BT RX thread): reset parser state
 * directly, defer the ring/handshake reset to the dispatch thread.
 */
void inputstick_reset(void)
{
	parse_state = IS_STATE_TAG;
	pkt_len = 0;
	pkt_total = 0;
	atomic_set(&reset_pending, 1);
	k_sem_give(&is_sem);
}

/* Called from usb_kbd.c when the host configures the HID interface: if the
 * handshake has already completed, this is what finally sends the Ready
 * notification (USB can enumerate after the BLE handshake).
 */
void inputstick_usb_ready(void)
{
	try_send_ready();
}
```

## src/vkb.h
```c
/* Voice Keyboard — internal interfaces */

#ifndef VKB_H_
#define VKB_H_

#include <stdint.h>
#include <stdbool.h>

/* --- app LED hooks (implemented in main.c, used by ble.c) --- */
void app_led_advertising(void);
void app_led_connected(void);
void app_led_off(void);

/* Temporary bring-up aid: red LED (led1) blink codes, see DEBUG_NOTES.md. */
enum app_led_code {
	APP_LED_RX_WRITE,	/* 1 short blink: NUS RX bytes received */
	APP_LED_HID_SENT,	/* 2 short blinks: host clocked out first report */
	APP_LED_HID_FAIL,	/* 3 blinks: HID report submit failed/not ready */
	APP_LED_HID_READY,	/* solid 1 s: host configured the HID interface */
	APP_LED_MOUSE_RX,	/* 4 short blinks: mouse report received */
	APP_LED_ABS_RX,		/* 5 short blinks: absolute pointer report received */
	APP_LED_MACRO_PLAY,	/* 6 short blinks: macro playback (v5 only; unused since v5.14) */
	/* Connect-stage trace (v5.3): 200 ms pulses, see DEBUG_NOTES.md. */
	APP_LED_CONN_REJECT,	/* 7: unbonded peer rejected (v5.3-v5.8; no trigger since v6.0) */
	APP_LED_SEC_FAIL,	/* 8: security/pairing failed (v5.3-v5.8; no trigger since v6.0) */
	APP_LED_TX_SUB,		/* 9: central subscribed to NUS TX */
	APP_LED_NAME_READ,	/* 10: first encrypted read done (v5.x only; no trigger since v6.0) */
	/* InputStick trace (v6.0): 200 ms pulses, see DEBUG_NOTES.md v6.0. */
	APP_LED_IS_CRC_FAIL,	/* 11: InputStick packet CRC mismatch (200ms x2) */
	APP_LED_IS_PKT,		/* 12: InputStick control packet dispatched (200ms x3) */
	APP_LED_IS_READY,	/* 13: handshake done, Ready notification sent (200ms x4) */
	/* v6.5-diagnostic: drain-count ground truth, see DEBUG_NOTES.md
	 * v6.5-diagnostic. Fired from send_hid_status() every status interval.
	 */
	APP_LED_DRAIN_NONZERO,	/* 14: 3 quick blinks — a nonzero drain was computed */
	APP_LED_DRAIN_ZERO,	/* 15: 1 long blink — all three drains are 0 */
};

void app_led_debug(enum app_led_code code);
/* v6.6-diagnostic: one-way drain latch (red LED solid = drain went nonzero
 * at least once). Implemented in main.c, called from inputstick.c.
 */
void app_drain_latch_set(void);
/* Boot-stage trace (v5.1): red blink N = boot stage N completed. */
void app_boot_stage(uint8_t stage);
/* Boot sub-stage markers (v5.2): long (400 ms) blinks, see DEBUG_NOTES.md. */
void app_boot_mark(uint8_t count);
/* Repeating fast blink: bt_enable() returned an error. Never returns. */
void app_boot_error_bt(void);
/* Repeating 3-long-blink group: settings storage unrecoverable. Never returns. */
void app_boot_error_settings(void);

/* --- USB HID composite keyboard + mouse (usb_kbd.c) --- */
int usb_kbd_init(void);
bool usb_kbd_ready(void);
/* Submit one keyboard report (report ID 1: mods + single key, 0 = none). */
int usb_kbd_report(uint8_t mods, uint8_t key);
/* Submit one mouse report (report ID 2). Deltas are clamped to [-127, 127]. */
int usb_mouse_report(uint8_t buttons, int dx, int dy, int wheel);
/* Submit one absolute pointer report (report ID 3). x/y: 0..32767. */
int usb_abs_report(uint8_t buttons, uint16_t x, uint16_t y);
/* Submit one consumer-control report (report ID 4): a 16-bit consumer
 * usage (media key). */
int usb_consumer_report(uint16_t usage);
/* Read and reset the per-interface "reports sent to host" drain counters
 * (keyboard / mouse / consumer). The absolute pointer and consumer-control
 * submits both count into the consumer figure (InputStick "consumer
 * queue"). Used by the periodic HIDStatusNotification. */
void usb_hid_drain_counts(uint8_t *kbd, uint8_t *mouse, uint8_t *consumer);
/* v6.7: read the drain counters WITHOUT resetting (peek) and, after the 0x2F
 * carrying those deltas has been accepted into the notify queue, subtract
 * exactly the reported deltas (commit). See usb_kbd.c for the lossless
 * peek-then-commit protocol. */
void usb_hid_drain_counts_peek(uint8_t *kbd, uint8_t *mouse, uint8_t *consumer);
void usb_hid_drain_counts_commit(uint8_t kbd, uint8_t mouse, uint8_t consumer);
/* v6.7: credit the consumer drain counter directly (no USB submit) for a
 * 0x22 report the descriptor cannot represent (System page, report ID 2) so
 * the app's per-report consumer accounting stays 1:1. */
void usb_hid_consumer_credit(uint8_t count);

/* --- BLE NUS peripheral (ble.c) --- */
int ble_init(void);
/* Queue a packet for NUS TX notify, deferred to the system workqueue
 * (best effort; the v5.4 rule — never bt_gatt_notify() from the BT RX
 * thread). Safe to call from any non-BT-RX thread. */
int ble_notify(const void *data, uint16_t len);
/* True while a BLE connection is active. */
bool ble_is_connected(void);

/* --- InputStick protocol layer (inputstick.c) --- */
/* Feed received NUS RX bytes into the packet parser (any chunking). */
void inputstick_feed(const void *data, uint16_t len);
/* Reset the parser + handshake state on disconnect. */
void inputstick_reset(void);
/* Called by usb_kbd.c when the host configures the HID interface: if the
 * handshake has already completed, emit the Ready HIDStatusNotification. */
void inputstick_usb_ready(void);

/* v6.0: the v2..v5 legacy raw ASCII/escape typing engine (typing.c) is
 * superseded by the InputStick packet protocol and removed from the build
 * for good — the file stays in the tree as a reference (see DEBUG_NOTES.md
 * v6.0). The v5.14 note about the removed macro store also still applies:
 * macro.c is out of the build and its declarations are gone (git history
 * v5.13, 1ce9ca0).
 */

#endif /* VKB_H_ */
```
